# ADuCM355 register map
Vendor: Analog Devices; Series: ADuCM355; File version: 1p0
CPU: CM3 r0p1, little endian, no MPU, no FPU, 3 interrupt priority bits
Registers are 32-bit, read-write, reset 0x0 unless marked. A register's access mark holds for its fields unless they carry their own. Offsets are from the block's base; [hi:lo] are bit positions.

## SPI0 — Serial Peripheral Interface
Base 0x40004000
Same registers: SPI2 0x40024000
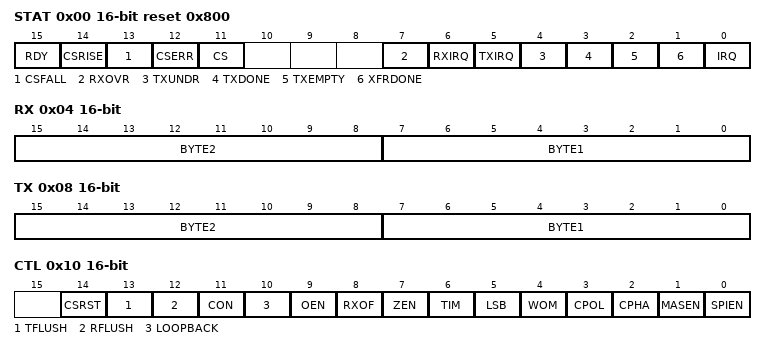
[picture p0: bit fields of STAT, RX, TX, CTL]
0x00 STAT 16-bit reset 0x800 — Status
  [15] RDY ro — Detected an edge on Ready indicator for flow-control
  [14] CSRISE ro — Detected a rising edge on CS, in slave CON mode
  [13] CSFALL ro — Detected a falling edge on CS, in slave CON mode
  [12] CSERR ro — Detected a CS error condition in slave mode
  [11] CS ro — CS Status
  [7] RXOVR ro — SPI Rx FIFO overflow
  [6] RXIRQ ro — SPI Rx IRQ
  [5] TXIRQ ro — SPI Tx IRQ
  [4] TXUNDR ro — SPI Tx FIFO underflow
  [3] TXDONE ro — SPI Tx Done in read command mode
  [2] TXEMPTY ro — SPI Tx FIFO empty interrupt
  [1] XFRDONE ro — SPI transfer completion
  [0] IRQ ro — SPI Interrupt status
0x04 RX 16-bit — Receive
  [15:8] BYTE2 ro — 8-bit receive buffer, used only in DMA modes
  [7:0] BYTE1 ro — 8-bit receive buffer
0x08 TX 16-bit — Transmit
  [15:8] BYTE2 wo range 0x00000000..0x000000FF — 8-bit transmit buffer, used only in DMA modes
  [7:0] BYTE1 wo range 0x00000000..0x000000FF — 8-bit transmit buffer
0x0C DIV 16-bit — SPI baud rate selection
  [5:0] VALUE range 0x00000000..0x0000003F — SPI clock divider
0x10 CTL 16-bit — SPI configuration 1
  [14] CSRST range 0x00000000..0x00000001 — Reset Mode for CS Error bit
  [13] TFLUSH range 0x00000000..0x00000001 — SPI Tx FIFO Flush enable
  [12] RFLUSH range 0x00000000..0x00000001 — SPI Rx FIFO Flush enable
  [11] CON range 0x00000000..0x00000001 — Continuous transfer enable
  [10] LOOPBACK range 0x00000000..0x00000001 — Loopback enable
  [9] OEN range 0x00000000..0x00000001 — Slave MISO output enable
  [8] RXOF range 0x00000000..0x00000001 — RX overflow overwrite enable
  [7] ZEN range 0x00000000..0x00000001 — Transmit zeros enable
  [6] TIM range 0x00000000..0x00000001 — SPI transfer and interrupt mode
  [5] LSB — LSB first transfer enable
  [4] WOM — SPI Wired Or mode
  [3] CPOL — Serial Clock Polarity
  [2] CPHA — Serial clock phase mode
  [1] MASEN — Master mode enable
  [0] SPIEN — SPI enable
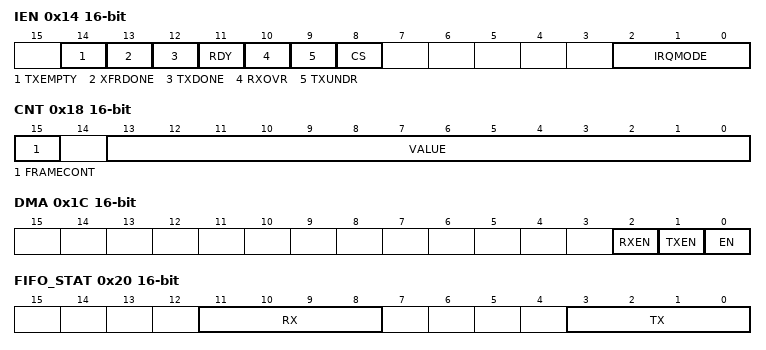
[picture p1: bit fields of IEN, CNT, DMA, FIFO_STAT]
0x14 IEN 16-bit — SPI configuration 2
  [14] TXEMPTY — Tx-FIFO Empty interrupt enable
  [13] XFRDONE — SPI transfer completion interrupt enable
  [12] TXDONE — SPI transmit done interrupt enable
  [11] RDY — Ready signal edge interrupt enable
  [10] RXOVR — Rx-overflow interrupt enable
  [9] TXUNDR — Tx-underflow interrupt enable
  [8] CS range 0x00000000..0x00000001 — Enable interrupt on every CS edge in slave CON mode
  [2:0] IRQMODE — SPI IRQ mode bits
0x18 CNT 16-bit — Transfer byte count
  [15] FRAMECONT — Continue frame
  [13:0] VALUE range 0x00000000..0x00003FFF — Transfer byte count
0x1C DMA 16-bit — SPI DMA enable
  [2] RXEN range 0x00000000..0x00000001 — Enable receive DMA request
  [1] TXEN range 0x00000000..0x00000001 — Enable transmit DMA request
  [0] EN range 0x00000000..0x00000001 — Enable DMA for data transfer
0x20 FIFO_STAT 16-bit — FIFO Status
  [11:8] RX ro — SPI Rx FIFO status
  [3:0] TX ro — SPI Tx FIFO status
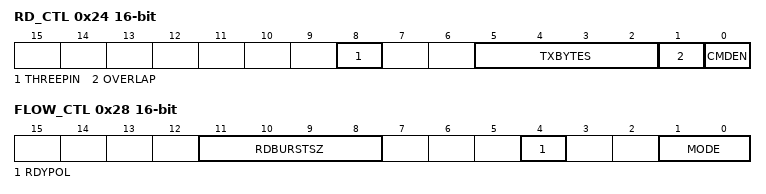
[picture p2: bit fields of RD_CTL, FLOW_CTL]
0x24 RD_CTL 16-bit — Read Control
  [8] THREEPIN — Three pin SPI mode
  [5:2] TXBYTES range 0x00000000..0x0000000F — Transmit byte count minus 1 for read command
  [1] OVERLAP — Tx/Rx Overlap mode
  [0] CMDEN — Read command enable
0x28 FLOW_CTL 16-bit — Flow Control
  [11:8] RDBURSTSZ range 0x00000000..0x0000000F — Read data burst size minus 1
  [4] RDYPOL — Polarity of RDY/MISO line
  [1:0] MODE — Flow control mode
0x2C WAIT_TMR 16-bit — Wait timer for flow control
  [15:0] VALUE range 0x00000000..0x0000FFFF — Wait timer for flow-control
0x30 CS_CTL 16-bit reset 0x1 — Chip-Select control for multi-slave connections
  [3:0] SEL range 0x00000000..0x0000000F — Chip-Select control
0x34 CS_OVERRIDE 16-bit — Chip-Select Override
  [1:0] CTL — CS Override Control
